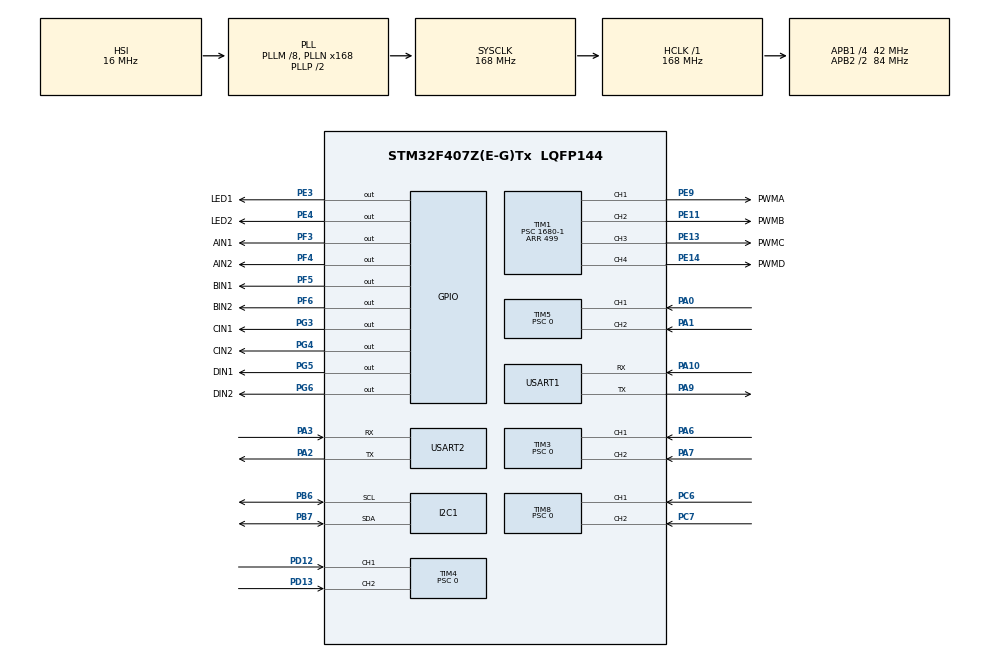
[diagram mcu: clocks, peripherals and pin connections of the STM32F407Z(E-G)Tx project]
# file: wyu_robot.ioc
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Dma.Request0=USART1_RX
Dma.Request1=USART1_TX
Dma.USART1_RX.0.Direction=DMA_PERIPH_TO_MEMORY
Dma.USART1_RX.0.FIFOMode=DMA_FIFOMODE_DISABLE
Dma.USART1_RX.0.Instance=DMA2_Stream2
Dma.USART1_RX.0.MemDataAlignment=DMA_MDATAALIGN_BYTE
Dma.USART1_RX.0.MemInc=DMA_MINC_ENABLE
Dma.USART1_RX.0.Mode=DMA_NORMAL
Dma.USART1_RX.0.PeriphDataAlignment=DMA_PDATAALIGN_BYTE
Dma.USART1_RX.0.PeriphInc=DMA_PINC_DISABLE
Dma.USART1_RX.0.Priority=DMA_PRIORITY_HIGH
Dma.USART1_TX.1.Direction=DMA_MEMORY_TO_PERIPH
Dma.USART1_TX.1.FIFOMode=DMA_FIFOMODE_DISABLE
Dma.USART1_TX.1.Instance=DMA2_Stream7
Dma.USART1_TX.1.MemDataAlignment=DMA_MDATAALIGN_BYTE
Dma.USART1_TX.1.MemInc=DMA_MINC_ENABLE
Dma.USART1_TX.1.Mode=DMA_NORMAL
Dma.USART1_TX.1.PeriphDataAlignment=DMA_PDATAALIGN_BYTE
Dma.USART1_TX.1.PeriphInc=DMA_PINC_DISABLE
Dma.USART1_TX.1.Priority=DMA_PRIORITY_HIGH
Mcu.Family=STM32F4
Mcu.Name=STM32F407Z(E-G)Tx
Mcu.Package=LQFP144
NVIC.DMA2_Stream2_IRQn=true\:0\:0\:false\:false\:true\:false\:true
NVIC.DMA2_Stream7_IRQn=true\:0\:0\:false\:false\:true\:false\:true
NVIC.PriorityGroup=NVIC_PRIORITYGROUP_4
NVIC.TIM6_DAC_IRQn=true\:0\:0\:false\:false\:true\:true\:true
NVIC.USART1_IRQn=true\:0\:0\:false\:false\:true\:true\:true
PA0-WKUP.Signal=S_TIM5_CH1
PA1.Signal=S_TIM5_CH2
PA10.Mode=Asynchronous
PA10.Signal=USART1_RX
PA13.Mode=Serial_Wire
PA13.Signal=SYS_JTMS-SWDIO
PA14.Mode=Serial_Wire
PA14.Signal=SYS_JTCK-SWCLK
PA2.Mode=Asynchronous
PA2.Signal=USART2_TX
PA3.Mode=Asynchronous
PA3.Signal=USART2_RX
PA6.Signal=S_TIM3_CH1
PA7.Signal=S_TIM3_CH2
PA9.Mode=Asynchronous
PA9.Signal=USART1_TX
PB6.Mode=I2C
PB6.Signal=I2C1_SCL
PB7.Mode=I2C
PB7.Signal=I2C1_SDA
PC6.Signal=S_TIM8_CH1
PC7.Signal=S_TIM8_CH2
PD12.Signal=S_TIM4_CH1
PD13.Signal=S_TIM4_CH2
PE11.GPIO_Label=PWMB
PE11.GPIO_PuPd=GPIO_PULLDOWN
PE11.Signal=S_TIM1_CH2
PE13.GPIO_Label=PWMC
PE13.GPIO_PuPd=GPIO_PULLDOWN
PE13.Signal=S_TIM1_CH3
PE14.GPIO_Label=PWMD
PE14.GPIO_PuPd=GPIO_PULLDOWN
PE14.Signal=S_TIM1_CH4
PE3.GPIO_Label=LED1
PE3.Signal=GPIO_Output
PE4.GPIO_Label=LED2
PE4.Signal=GPIO_Output
PE9.GPIO_Label=PWMA
PE9.GPIO_PuPd=GPIO_PULLDOWN
PE9.Signal=S_TIM1_CH1
PF3.GPIO_Label=AIN1
PF3.Signal=GPIO_Output
PF4.GPIO_Label=AIN2
PF4.Signal=GPIO_Output
PF5.GPIO_Label=BIN1
PF5.Signal=GPIO_Output
PF6.GPIO_Label=BIN2
PF6.Signal=GPIO_Output
PG3.GPIO_Label=CIN1
PG3.Signal=GPIO_Output
PG4.GPIO_Label=CIN2
PG4.Signal=GPIO_Output
PG5.GPIO_Label=DIN1
PG5.Signal=GPIO_Output
PG6.GPIO_Label=DIN2
PG6.Signal=GPIO_Output
PH0-OSC_IN.Mode=HSE-External-Oscillator
PH0-OSC_IN.Signal=RCC_OSC_IN
PH1-OSC_OUT.Mode=HSE-External-Oscillator
PH1-OSC_OUT.Signal=RCC_OSC_OUT
ProjectManager.HeapSize=0x200
ProjectManager.StackSize=0x400
ProjectManager.TargetToolchain=MDK-ARM V5
RCC.48MHZClocksFreq_Value=84000000
RCC.AHBFreq_Value=168000000
RCC.APB1CLKDivider=RCC_HCLK_DIV4
RCC.APB1Freq_Value=42000000
RCC.APB1TimFreq_Value=84000000
RCC.APB2CLKDivider=RCC_HCLK_DIV2
RCC.APB2Freq_Value=84000000
RCC.APB2TimFreq_Value=168000000
RCC.CortexFreq_Value=168000000
RCC.HCLKFreq_Value=168000000
RCC.HSE_VALUE=25000000
RCC.HSI_VALUE=16000000
RCC.LSE_VALUE=32768
RCC.PLLM=8
RCC.PLLN=168
RCC.SYSCLKFreq_VALUE=168000000
RCC.SYSCLKSource=RCC_SYSCLKSOURCE_PLLCLK
RCC.VCOOutputFreq_Value=336000000
SH.S_TIM1_CH1.0=TIM1_CH1,PWM Generation1 CH1
SH.S_TIM1_CH2.0=TIM1_CH2,PWM Generation2 CH2
SH.S_TIM1_CH3.0=TIM1_CH3,PWM Generation3 CH3
SH.S_TIM1_CH4.0=TIM1_CH4,PWM Generation4 CH4
SH.S_TIM3_CH1.0=TIM3_CH1,Encoder_Interface
SH.S_TIM3_CH2.0=TIM3_CH2,Encoder_Interface
SH.S_TIM4_CH1.0=TIM4_CH1,Encoder_Interface
SH.S_TIM4_CH2.0=TIM4_CH2,Encoder_Interface
SH.S_TIM5_CH1.0=TIM5_CH1,Encoder_Interface
SH.S_TIM5_CH2.0=TIM5_CH2,Encoder_Interface
SH.S_TIM8_CH1.0=TIM8_CH1,Encoder_Interface
SH.S_TIM8_CH2.0=TIM8_CH2,Encoder_Interface
TIM1.Channel-PWM\ Generation1\ CH1=TIM_CHANNEL_1
TIM1.Channel-PWM\ Generation2\ CH2=TIM_CHANNEL_2
TIM1.Channel-PWM\ Generation3\ CH3=TIM_CHANNEL_3
TIM1.Channel-PWM\ Generation4\ CH4=TIM_CHANNEL_4
TIM1.Period=499
TIM1.Prescaler=1680-1
TIM2.Period=0xffffffff
TIM2.Prescaler=16800
TIM3.Period=65535
TIM3.Prescaler=0
TIM4.Period=65535
TIM4.Prescaler=0
TIM5.Period=65535
TIM5.Prescaler=0
TIM6.Period=10000-1
TIM6.Prescaler=840-1
TIM8.Period=65535
TIM8.Prescaler=0
USART1.VirtualMode=VM_ASYNC
USART2.VirtualMode=VM_ASYNC
VP_TIM2_VS_ClockSourceINT.Mode=Internal
VP_TIM6_VS_ClockSourceINT.Mode=Enable_Timer
board=custom

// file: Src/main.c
/* USER CODE BEGIN Header */
/**
  ******************************************************************************
  * @file           : main.c
  * @brief          : Main program body
  ******************************************************************************
  ** This notice applies to any and all portions of this file
  * that are not between comment pairs USER CODE BEGIN and
  * USER CODE END. Other portions of this file, whether
  * inserted by the user or by software development tools
  * are owned by their respective copyright owners.
  *
  * COPYRIGHT(c) 2019 STMicroelectronics
  *
  * Redistribution and use in source and binary forms, with or without modification,
  * are permitted provided that the following conditions are met:
  *   1. Redistributions of source code must retain the above copyright notice,
  *      this list of conditions and the following disclaimer.
  *   2. Redistributions in binary form must reproduce the above copyright notice,
  *      this list of conditions and the following disclaimer in the documentation
  *      and/or other materials provided with the distribution.
  *   3. Neither the name of STMicroelectronics nor the names of its contributors
  *      may be used to endorse or promote products derived from this software
  *      without specific prior written permission.
  *
  * THIS SOFTWARE IS PROVIDED BY THE COPYRIGHT HOLDERS AND CONTRIBUTORS "AS IS"
  * AND ANY EXPRESS OR IMPLIED WARRANTIES, INCLUDING, BUT NOT LIMITED TO, THE
  * IMPLIED WARRANTIES OF MERCHANTABILITY AND FITNESS FOR A PARTICULAR PURPOSE ARE
  * DISCLAIMED. IN NO EVENT SHALL THE COPYRIGHT HOLDER OR CONTRIBUTORS BE LIABLE
  * FOR ANY DIRECT, INDIRECT, INCIDENTAL, SPECIAL, EXEMPLARY, OR CONSEQUENTIAL
  * DAMAGES (INCLUDING, BUT NOT LIMITED TO, PROCUREMENT OF SUBSTITUTE GOODS OR
  * SERVICES; LOSS OF USE, DATA, OR PROFITS; OR BUSINESS INTERRUPTION) HOWEVER
  * CAUSED AND ON ANY THEORY OF LIABILITY, WHETHER IN CONTRACT, STRICT LIABILITY,
  * OR TORT (INCLUDING NEGLIGENCE OR OTHERWISE) ARISING IN ANY WAY OUT OF THE USE
  * OF THIS SOFTWARE, EVEN IF ADVISED OF THE POSSIBILITY OF SUCH DAMAGE.
  *
  ******************************************************************************
  */
/* USER CODE END Header */

#include "main.h"
#include "dma.h"
#include "i2c.h"
#include "tim.h"
#include "usart.h"
#include "gpio.h"

/* USER CODE BEGIN Includes */
#include "mainpp.h"
/* USER CODE END Includes */

void SystemClock_Config(void);

int main(void)
{

  /* MCU Configuration--------------------------------------------------------*/

  /* Reset of all peripherals, Initializes the Flash interface and the Systick. */
  HAL_Init();

  /* Configure the system clock */
  SystemClock_Config();

  /* Initialize all configured peripherals */
  MX_GPIO_Init();
  MX_DMA_Init();
  MX_TIM2_Init();
  MX_USART1_UART_Init();
  MX_TIM3_Init();
  MX_TIM4_Init();
  MX_TIM5_Init();
  MX_TIM8_Init();
  MX_I2C1_Init();
  MX_USART2_UART_Init();
  MX_TIM1_Init();
  MX_TIM6_Init();
  /* USER CODE BEGIN 2 */
	HAL_TIM_Base_Start_IT(&htim6);
	HAL_TIM_Encoder_Start(&htim3, TIM_CHANNEL_ALL);//����A�ֱ�����
  HAL_TIM_Encoder_Start(&htim4, TIM_CHANNEL_ALL);//����B�ֱ�����
  HAL_TIM_Encoder_Start(&htim5, TIM_CHANNEL_ALL);//����C�ֱ�����
  HAL_TIM_Encoder_Start(&htim8, TIM_CHANNEL_ALL);//����D�ֱ�����

	HAL_TIM_PWM_Start(&htim1, TIM_CHANNEL_1);	//����A��PWM
	HAL_TIM_PWM_Start(&htim1, TIM_CHANNEL_2);	//����B��PWM
	HAL_TIM_PWM_Start(&htim1, TIM_CHANNEL_3);	//����C��PWM
	HAL_TIM_PWM_Start(&htim1, TIM_CHANNEL_4);	//����D��PWM

	setup();
  /* USER CODE END 2 */

  /* Infinite loop */
  /* USER CODE BEGIN WHILE */
  while (1)
  {
		loop();
    /* USER CODE END WHILE */

  }
}

void SystemClock_Config(void)
{
  RCC_OscInitTypeDef RCC_OscInitStruct = {0};
  RCC_ClkInitTypeDef RCC_ClkInitStruct = {0};

  /**Configure the main internal regulator output voltage
  */
  __HAL_RCC_PWR_CLK_ENABLE();
  __HAL_PWR_VOLTAGESCALING_CONFIG(PWR_REGULATOR_VOLTAGE_SCALE1);
  /**Initializes the CPU, AHB and APB busses clocks
  */
  RCC_OscInitStruct.OscillatorType = RCC_OSCILLATORTYPE_HSI;
  RCC_OscInitStruct.HSIState = RCC_HSI_ON;
  RCC_OscInitStruct.HSICalibrationValue = RCC_HSICALIBRATION_DEFAULT;
  RCC_OscInitStruct.PLL.PLLState = RCC_PLL_ON;
  RCC_OscInitStruct.PLL.PLLSource = RCC_PLLSOURCE_HSI;
  RCC_OscInitStruct.PLL.PLLM = 8;
  RCC_OscInitStruct.PLL.PLLN = 168;
  RCC_OscInitStruct.PLL.PLLP = RCC_PLLP_DIV2;
  RCC_OscInitStruct.PLL.PLLQ = 4;
  if (HAL_RCC_OscConfig(&RCC_OscInitStruct) != HAL_OK)
  {
    Error_Handler();
  }
  /**Initializes the CPU, AHB and APB busses clocks
  */
  RCC_ClkInitStruct.ClockType = RCC_CLOCKTYPE_HCLK|RCC_CLOCKTYPE_SYSCLK
                              |RCC_CLOCKTYPE_PCLK1|RCC_CLOCKTYPE_PCLK2;
  RCC_ClkInitStruct.SYSCLKSource = RCC_SYSCLKSOURCE_PLLCLK;
  RCC_ClkInitStruct.AHBCLKDivider = RCC_SYSCLK_DIV1;
  RCC_ClkInitStruct.APB1CLKDivider = RCC_HCLK_DIV4;
  RCC_ClkInitStruct.APB2CLKDivider = RCC_HCLK_DIV2;

  if (HAL_RCC_ClockConfig(&RCC_ClkInitStruct, FLASH_LATENCY_5) != HAL_OK)
  {
    Error_Handler();
  }
}

void Error_Handler(void)
{
}

/************************ (C) COPYRIGHT STMicroelectronics *****END OF FILE****/
